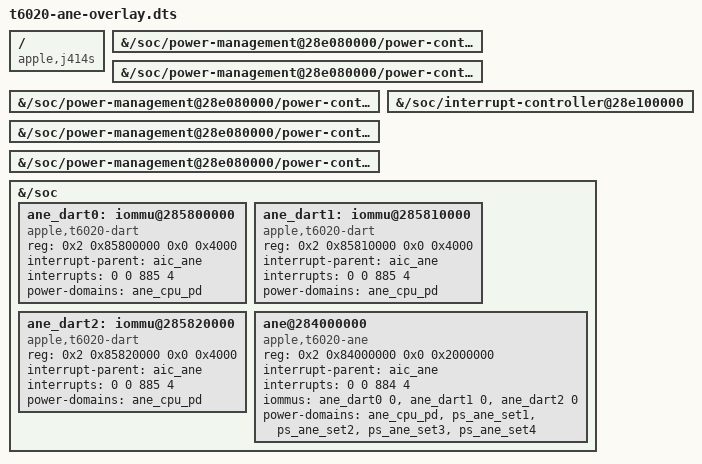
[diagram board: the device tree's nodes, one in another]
// SPDX-License-Identifier: GPL-2.0+ OR MIT
/* Generated by mlx-omarchy scripts/ane_soc_from_collect.py from
 * community deep submissions: macOS 4e8224a39f40; Linux 029744bb886f (soc t6020).
 *
 * SET MMIO (driver ps_base) = 0x28e08c000: the macOS
 * driver-window candidate at pmgr+0xc000, translated with the
 * high bits of the attested Linux pmgr block. The device tree's
 * ane_set* pwrstate cells are 4-byte power-controller cells,
 * never the SET MMIO base. RECOGNIZED tier: nothing here has
 * executed on silicon; the SET block is mapped read-only.
 *
 * macOS dart-ane0 reg ranges (translated where used):
 *   0x85800000/0x4000, 0x85810000/0x4000, 0x85820000/0x4000, 0x85804000/0x4000
 */
/dts-v1/;
/plugin/;

/ {
	compatible = "apple,j414s", "apple,t6020";

	fragment@0 {
		target-path = "/soc/power-management@28e080000/power-controller@2e0";
		ane_cpu_pd: __overlay__ {
		};
	};

	fragment@1 {
		target-path = "/soc/power-management@28e080000/power-controller@4018";
		ps_ane_set1: __overlay__ {
		};
	};

	fragment@2 {
		target-path = "/soc/power-management@28e080000/power-controller@4020";
		ps_ane_set2: __overlay__ {
		};
	};

	fragment@3 {
		target-path = "/soc/power-management@28e080000/power-controller@4028";
		ps_ane_set3: __overlay__ {
		};
	};

	fragment@4 {
		target-path = "/soc/power-management@28e080000/power-controller@4030";
		ps_ane_set4: __overlay__ {
		};
	};

	fragment@5 {
		target-path = "/soc/interrupt-controller@28e100000";
		aic_ane: __overlay__ {
		};
	};

	fragment@6 {
		target-path = "/soc";
		__overlay__ {
			#address-cells = <2>;
			#size-cells = <2>;
			ane_dart0: iommu@285800000 {
				compatible = "apple,t6020-dart";
				reg = <0x2 0x85800000 0x0 0x4000>;
				#iommu-cells = <1>;
				interrupt-parent = <&aic_ane>;
				interrupts = <0 0 885 4>;
				power-domains = <&ane_cpu_pd>;
				status = "okay";
			};
			ane_dart1: iommu@285810000 {
				compatible = "apple,t6020-dart";
				reg = <0x2 0x85810000 0x0 0x4000>;
				#iommu-cells = <1>;
				interrupt-parent = <&aic_ane>;
				interrupts = <0 0 885 4>;
				power-domains = <&ane_cpu_pd>;
				status = "okay";
			};
			ane_dart2: iommu@285820000 {
				compatible = "apple,t6020-dart";
				reg = <0x2 0x85820000 0x0 0x4000>;
				#iommu-cells = <1>;
				interrupt-parent = <&aic_ane>;
				interrupts = <0 0 885 4>;
				power-domains = <&ane_cpu_pd>;
				status = "okay";
			};
			ane@284000000 {
				compatible = "apple,t6020-ane";
				reg-names = "engine";
				reg = <0x2 0x84000000 0x0 0x2000000>;
				interrupt-parent = <&aic_ane>;
				interrupt-names = "ane";
				interrupts = <0 0 884 4>;
				iommus = <&ane_dart0 0>, <&ane_dart1 0>, <&ane_dart2 0>;
				power-domains = <&ane_cpu_pd>, <&ps_ane_set1>, <&ps_ane_set2>, <&ps_ane_set3>, <&ps_ane_set4>;
				status = "okay";
			};
		};
	};
};
